VERSION "MiLa comma 4 physical-link bench test v1"

NS_ :

BS_:

BU_: ESP32 COMMA4

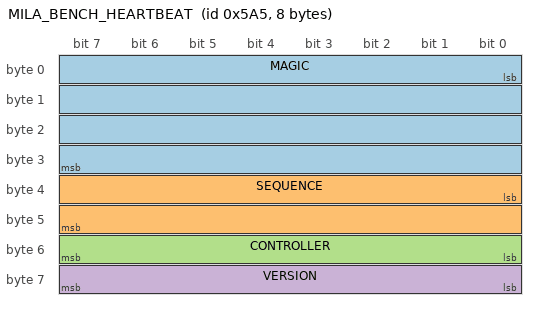
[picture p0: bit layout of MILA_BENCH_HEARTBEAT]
BO_ 1445 MILA_BENCH_HEARTBEAT: 8 ESP32
 SG_ MAGIC : 0|32@1+ (1,0) [0|4294967295] "" COMMA4
 SG_ SEQUENCE : 32|16@1+ (1,0) [0|65535] "" COMMA4
 SG_ CONTROLLER : 48|8@1+ (1,0) [0|255] "" COMMA4
 SG_ VERSION : 56|8@1+ (1,0) [0|255] "" COMMA4

CM_ BO_ 1445 "Bench-only heartbeat; do not add to the Nissan production DBC.";
CM_ SG_ 1445 MAGIC "Little-endian integer 0x414C494D, raw bytes spell MILA.";
VAL_ 1445 CONTROLLER 21 "MCP2515" 24 "MCP2518FD";
